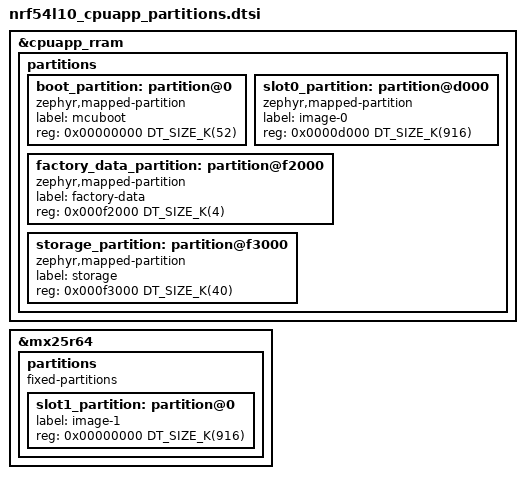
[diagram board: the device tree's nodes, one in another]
/*
 * Copyright (c) 2026 Nordic Semiconductor ASA
 *
 * SPDX-License-Identifier: LicenseRef-Nordic-5-Clause
 */

/delete-node/ &boot_partition;
/delete-node/ &slot0_partition;
/delete-node/ &slot1_partition;
/delete-node/ &storage_partition;

&cpuapp_rram {
	partitions {
		boot_partition: partition@0 {
			compatible = "zephyr,mapped-partition";
			label = "mcuboot";
			reg = <0x00000000 DT_SIZE_K(52)>;
		};

		slot0_partition: partition@d000 {
			compatible = "zephyr,mapped-partition";
			label = "image-0";
			reg = <0x0000d000 DT_SIZE_K(916)>;
		};

		factory_data_partition: partition@f2000 {
			compatible = "zephyr,mapped-partition";
			label = "factory-data";
			reg = <0x000f2000 DT_SIZE_K(4)>;
		};

		storage_partition: partition@f3000 {
			compatible = "zephyr,mapped-partition";
			label = "storage";
			reg = <0x000f3000 DT_SIZE_K(40)>;
		};
	};
};

&mx25r64 {
	status = "okay";

	partitions {
		compatible = "fixed-partitions";
		#address-cells = <1>;
		#size-cells = <1>;

		slot1_partition: partition@0 {
			label = "image-1";
			reg = <0x00000000 DT_SIZE_K(916)>;
		};
	};
};
